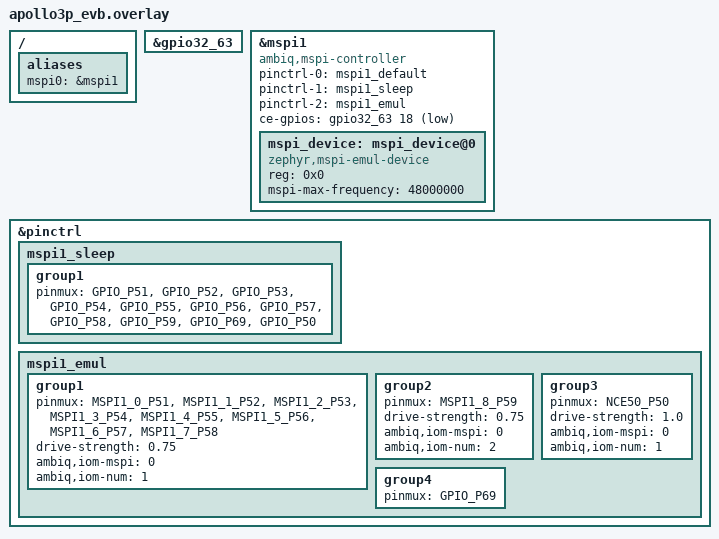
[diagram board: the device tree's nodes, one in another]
/*
 * Copyright (c) 2024 Ambiq Micro Inc. <www.ambiq.com>
 * SPDX-License-Identifier: Apache-2.0
 */

/ {
	aliases {
		mspi0 = &mspi1;
	};
};

&gpio32_63 {
	status = "okay";
};

&mspi1 {

	compatible = "ambiq,mspi-controller";
	pinctrl-0 = <&mspi1_default>;
	pinctrl-1 = <&mspi1_sleep>;
	pinctrl-2 = <&mspi1_emul>;
	status = "okay";

	ce-gpios = <&gpio32_63 18 GPIO_ACTIVE_LOW>;

	mspi_device: mspi_device@0 {
		status = "okay";
		compatible = "zephyr,mspi-emul-device";
		reg = <0x0>;
		mspi-max-frequency = <48000000>;
	};
};

&pinctrl {

	mspi1_sleep: mspi1_sleep {
		group1 {
			pinmux = <GPIO_P51>,
				 <GPIO_P52>,
				 <GPIO_P53>,
				 <GPIO_P54>,
				 <GPIO_P55>,
				 <GPIO_P56>,
				 <GPIO_P57>,
				 <GPIO_P58>,
				 <GPIO_P59>,
				 <GPIO_P69>,
				 <GPIO_P50>;
		};
	};

	mspi1_emul: mspi1_emul {

		group1 {
			pinmux = <MSPI1_0_P51>,
				 <MSPI1_1_P52>,
				 <MSPI1_2_P53>,
				 <MSPI1_3_P54>,
				 <MSPI1_4_P55>,
				 <MSPI1_5_P56>,
				 <MSPI1_6_P57>,
				 <MSPI1_7_P58>;
			drive-strength = "0.75";
			ambiq,iom-mspi = <0>;
			ambiq,iom-num = <1>;
		};

		group2 {
			pinmux = <MSPI1_8_P59>;
			drive-strength = "0.75";
			ambiq,iom-mspi = <0>;
			ambiq,iom-num = <2>;
		};

		group3 {
			pinmux = <NCE50_P50>;
			drive-strength = "1.0";
			ambiq,iom-mspi = <0>;
			ambiq,iom-num = <1>;
		};

		group4 {
			pinmux = <GPIO_P69>;
		};
	};
};
